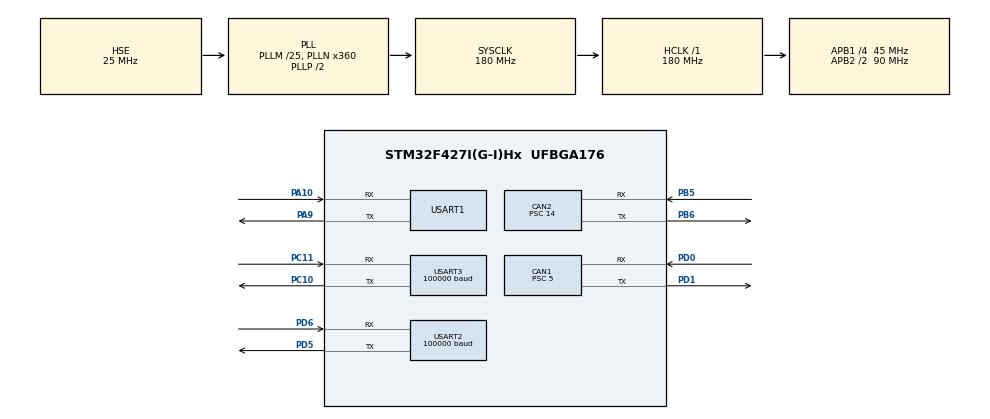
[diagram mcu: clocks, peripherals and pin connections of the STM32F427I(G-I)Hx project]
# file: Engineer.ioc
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CAN1.ABOM=ENABLE
CAN1.BS1=CAN_BS1_4TQ
CAN1.BS2=CAN_BS2_4TQ
CAN1.CalculateBaudRate=1000000
CAN1.CalculateTimeBit=1000
CAN1.CalculateTimeQuantum=111.11111111111111
CAN1.Prescaler=5
CAN2.ABOM=ENABLE
CAN2.BS1=CAN_BS1_4TQ
CAN2.BS2=CAN_BS2_4TQ
CAN2.CalculateBaudRate=357142
CAN2.CalculateTimeBit=2800
CAN2.CalculateTimeQuantum=311.1111111111111
CAN2.Prescaler=14
Dma.Request0=USART3_RX
Dma.Request1=USART1_RX
Dma.Request2=USART1_TX
Dma.USART1_RX.1.Direction=DMA_PERIPH_TO_MEMORY
Dma.USART1_RX.1.FIFOMode=DMA_FIFOMODE_DISABLE
Dma.USART1_RX.1.Instance=DMA2_Stream2
Dma.USART1_RX.1.MemDataAlignment=DMA_MDATAALIGN_BYTE
Dma.USART1_RX.1.MemInc=DMA_MINC_ENABLE
Dma.USART1_RX.1.Mode=DMA_NORMAL
Dma.USART1_RX.1.PeriphDataAlignment=DMA_PDATAALIGN_BYTE
Dma.USART1_RX.1.PeriphInc=DMA_PINC_DISABLE
Dma.USART1_RX.1.Priority=DMA_PRIORITY_LOW
Dma.USART1_TX.2.Direction=DMA_MEMORY_TO_PERIPH
Dma.USART1_TX.2.FIFOMode=DMA_FIFOMODE_DISABLE
Dma.USART1_TX.2.Instance=DMA2_Stream7
Dma.USART1_TX.2.MemDataAlignment=DMA_MDATAALIGN_BYTE
Dma.USART1_TX.2.MemInc=DMA_MINC_ENABLE
Dma.USART1_TX.2.Mode=DMA_NORMAL
Dma.USART1_TX.2.PeriphDataAlignment=DMA_PDATAALIGN_BYTE
Dma.USART1_TX.2.PeriphInc=DMA_PINC_DISABLE
Dma.USART1_TX.2.Priority=DMA_PRIORITY_LOW
Dma.USART3_RX.0.Direction=DMA_PERIPH_TO_MEMORY
Dma.USART3_RX.0.FIFOMode=DMA_FIFOMODE_DISABLE
Dma.USART3_RX.0.Instance=DMA1_Stream1
Dma.USART3_RX.0.MemDataAlignment=DMA_MDATAALIGN_BYTE
Dma.USART3_RX.0.MemInc=DMA_MINC_ENABLE
Dma.USART3_RX.0.Mode=DMA_NORMAL
Dma.USART3_RX.0.PeriphDataAlignment=DMA_PDATAALIGN_BYTE
Dma.USART3_RX.0.PeriphInc=DMA_PINC_DISABLE
Dma.USART3_RX.0.Priority=DMA_PRIORITY_LOW
Mcu.Family=STM32F4
Mcu.Name=STM32F427I(G-I)Hx
Mcu.Package=UFBGA176
NVIC.CAN1_RX0_IRQn=true\:0\:0\:false\:false\:true\:true\:true
NVIC.CAN2_RX0_IRQn=true\:0\:0\:false\:false\:true\:true\:true
NVIC.DMA1_Stream1_IRQn=true\:0\:0\:false\:false\:true\:false\:true
NVIC.DMA2_Stream2_IRQn=true\:0\:0\:false\:false\:true\:false\:true
NVIC.DMA2_Stream7_IRQn=true\:0\:0\:false\:false\:true\:false\:true
NVIC.PriorityGroup=NVIC_PRIORITYGROUP_4
NVIC.TIM6_DAC_IRQn=true\:0\:0\:false\:false\:true\:true\:true
NVIC.USART1_IRQn=true\:0\:0\:false\:false\:true\:true\:true
NVIC.USART2_IRQn=true\:0\:0\:false\:false\:true\:true\:true
NVIC.USART3_IRQn=true\:0\:0\:false\:false\:true\:true\:true
PA0/WKUP.Signal=S_TIM2_CH1_ETR
PA1.Signal=S_TIM2_CH2
PA10.Mode=Asynchronous
PA10.Signal=USART1_RX
PA13.Mode=Serial_Wire
PA13.Signal=SYS_JTMS-SWDIO
PA14.Mode=Serial_Wire
PA14.Signal=SYS_JTCK-SWCLK
PA9.Mode=Asynchronous
PA9.Signal=USART1_TX
PB5.Mode=CAN_Activate
PB5.Signal=CAN2_RX
PB6.Mode=CAN_Activate
PB6.Signal=CAN2_TX
PC10.Mode=Asynchronous
PC10.Signal=USART3_TX
PC11.Mode=Asynchronous
PC11.Signal=USART3_RX
PD0.Mode=CAN_Activate
PD0.Signal=CAN1_RX
PD1.Mode=CAN_Activate
PD1.Signal=CAN1_TX
PD5.Mode=Asynchronous
PD5.Signal=USART2_TX
PD6.Mode=Asynchronous
PD6.Signal=USART2_RX
PH0/OSC_IN.Mode=HSE-External-Oscillator
PH0/OSC_IN.Signal=RCC_OSC_IN
PH1/OSC_OUT.Mode=HSE-External-Oscillator
PH1/OSC_OUT.Signal=RCC_OSC_OUT
ProjectManager.HeapSize=0x200
ProjectManager.StackSize=0x400
ProjectManager.TargetToolchain=MDK-ARM V5
RCC.48MHZClocksFreq_Value=90000000
RCC.AHBFreq_Value=180000000
RCC.APB1CLKDivider=RCC_HCLK_DIV4
RCC.APB1Freq_Value=45000000
RCC.APB1TimFreq_Value=90000000
RCC.APB2CLKDivider=RCC_HCLK_DIV2
RCC.APB2Freq_Value=90000000
RCC.APB2TimFreq_Value=180000000
RCC.CortexFreq_Value=180000000
RCC.HCLKFreq_Value=180000000
RCC.HSE_VALUE=25000000
RCC.HSI_VALUE=16000000
RCC.LSE_VALUE=32768
RCC.PLLM=25
RCC.PLLN=360
RCC.PLLSourceVirtual=RCC_PLLSOURCE_HSE
RCC.SYSCLKFreq_VALUE=180000000
RCC.SYSCLKSource=RCC_SYSCLKSOURCE_PLLCLK
RCC.VCOOutputFreq_Value=360000000
SH.S_TIM2_CH1_ETR.0=TIM2_CH1
SH.S_TIM2_CH2.0=TIM2_CH2
TIM6.AutoReloadPreload=TIM_AUTORELOAD_PRELOAD_DISABLE
TIM6.Period=10-1
TIM6.Prescaler=9000-1
USART1.VirtualMode=VM_ASYNC
USART2.BaudRate=100000
USART2.VirtualMode=VM_ASYNC
USART3.BaudRate=100000
USART3.VirtualMode=VM_ASYNC
VP_TIM6_VS_ClockSourceINT.Mode=Enable_Timer
board=custom

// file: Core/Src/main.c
/* USER CODE BEGIN Header */
/**
  ******************************************************************************
  * @file           : main.c
  * @brief          : Main program body
  ******************************************************************************
  * @attention
  *
  * Copyright (c) 2021 STMicroelectronics.
  * All rights reserved.
  *
  * This software is licensed under terms that can be found in the LICENSE file
  * in the root directory of this software component.
  * If no LICENSE file comes with this software, it is provided AS-IS.
  *
  ******************************************************************************
  */
/* USER CODE END Header */
#include "main.h"
#include "can.h"
#include "dma.h"
#include "tim.h"
#include "usart.h"
#include "gpio.h"

/* USER CODE BEGIN Includes */
#include "BSP_Chassis.h"
#include "BSP_Handle.h"
#include "BSP_Flip.h"
#include "BSP_Mineral.h"
#include "BSP_Uart.h"
/* USER CODE END Includes */

void SystemClock_Config(void);
/* USER CODE BEGIN PFP */
static void BSP_Init(void);

/* USER CODE END PFP */

int main(void)
{

  /* MCU Configuration--------------------------------------------------------*/

  /* Reset of all peripherals, Initializes the Flash interface and the Systick. */
  HAL_Init();

  /* Configure the system clock */
  SystemClock_Config();

  /* Initialize all configured peripherals */
  MX_GPIO_Init();
  MX_CAN1_Init();
  MX_CAN2_Init();
  MX_DMA_Init();
  MX_USART3_UART_Init();
  MX_TIM6_Init();
  MX_USART1_UART_Init();
  MX_USART2_UART_Init();
  /* USER CODE BEGIN 2 */
	BSP_Init();

  /* USER CODE END 2 */

  /* Infinite loop */
  while (1)
  {

  }
}

void SystemClock_Config(void)
{
  RCC_OscInitTypeDef RCC_OscInitStruct = {0};
  RCC_ClkInitTypeDef RCC_ClkInitStruct = {0};

  /** Configure the main internal regulator output voltage
  */
  __HAL_RCC_PWR_CLK_ENABLE();
  __HAL_PWR_VOLTAGESCALING_CONFIG(PWR_REGULATOR_VOLTAGE_SCALE1);
  /** Initializes the RCC Oscillators according to the specified parameters
  * in the RCC_OscInitTypeDef structure.
  */
  RCC_OscInitStruct.OscillatorType = RCC_OSCILLATORTYPE_HSE;
  RCC_OscInitStruct.HSEState = RCC_HSE_ON;
  RCC_OscInitStruct.PLL.PLLState = RCC_PLL_ON;
  RCC_OscInitStruct.PLL.PLLSource = RCC_PLLSOURCE_HSE;
  RCC_OscInitStruct.PLL.PLLM = 25;
  RCC_OscInitStruct.PLL.PLLN = 360;
  RCC_OscInitStruct.PLL.PLLP = RCC_PLLP_DIV2;
  RCC_OscInitStruct.PLL.PLLQ = 4;
  if (HAL_RCC_OscConfig(&RCC_OscInitStruct) != HAL_OK)
  {
    Error_Handler();
  }
  /** Activate the Over-Drive mode
  */
  if (HAL_PWREx_EnableOverDrive() != HAL_OK)
  {
    Error_Handler();
  }
  /** Initializes the CPU, AHB and APB buses clocks
  */
  RCC_ClkInitStruct.ClockType = RCC_CLOCKTYPE_HCLK|RCC_CLOCKTYPE_SYSCLK
                              |RCC_CLOCKTYPE_PCLK1|RCC_CLOCKTYPE_PCLK2;
  RCC_ClkInitStruct.SYSCLKSource = RCC_SYSCLKSOURCE_PLLCLK;
  RCC_ClkInitStruct.AHBCLKDivider = RCC_SYSCLK_DIV1;
  RCC_ClkInitStruct.APB1CLKDivider = RCC_HCLK_DIV4;
  RCC_ClkInitStruct.APB2CLKDivider = RCC_HCLK_DIV2;

  if (HAL_RCC_ClockConfig(&RCC_ClkInitStruct, FLASH_LATENCY_5) != HAL_OK)
  {
    Error_Handler();
  }
}

/* USER CODE BEGIN 4 */
void BSP_Init(void)
{
}
/* USER CODE END 4 */

void Error_Handler(void)
{
  __disable_irq();
  while (1)
  {
  }
}
